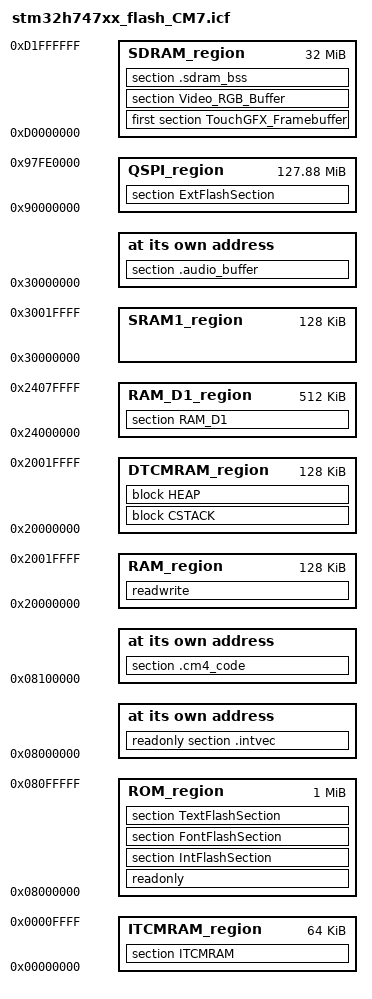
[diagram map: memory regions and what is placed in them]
/*###ICF### Section handled by ICF editor, don't touch! ****/
/*-Editor annotation file-*/
/* IcfEditorFile="$TOOLKIT_DIR$\config\ide\IcfEditor\cortex_v1_0.xml" */
/*-Specials-*/
/*-Start of  symbols-Auto-generated By STM32CubeMX*/
define symbol __ICFEDIT_region_ITCMRAM_start__ =0x00000000;
define symbol __ICFEDIT_region_ITCMRAM_end__ =0xFFFF;
define symbol __ICFEDIT_region_RAM_D1_start__ =0x24000000;
define symbol __ICFEDIT_region_RAM_D1_end__ =0x2407FFFF;
/*-End of MX Symbols*/

define symbol __ICFEDIT_intvec_start__ = 0x08000000;
/*-Memory Regions-*/
define symbol __ICFEDIT_region_ROM_start__     = 0x08000000;
define symbol __ICFEDIT_region_ROM_end__       = 0x80FFFFF;
define symbol __ICFEDIT_region_RAM_start__     = 0x20000000;
define symbol __ICFEDIT_region_RAM_end__       = 0x2001FFFF;
define symbol __ICFEDIT_region_ITCMRAM_start__ = 0x00000000;
define symbol __ICFEDIT_region_ITCMRAM_end__   = 0x0000FFFF;
define symbol __ICFEDIT_region_DTCMRAM_start__ = 0x20000000;
define symbol __ICFEDIT_region_DTCMRAM_end__   = 0x2001FFFF;
define symbol __ICFEDIT_region_SRAM1_start__   = 0x30000000;
define symbol __ICFEDIT_region_SRAM1_end__     = 0x3001FFFF;
/*-Sizes-*/
define symbol __ICFEDIT_size_cstack__ = 0x2000;  /* 8KB — IAR reported 96% used at 4KB */
define symbol __ICFEDIT_size_heap__   = 0x1000;
/**** End of ICF editor section. ###ICF###*/

/*-Quad-SPI Memory Regions-*/
define symbol __ICFEDIT_region_SDRAM_start__   = 0xD0000000;
define symbol __ICFEDIT_region_SDRAM_end__     = 0xD1FFFFFF;
define symbol __ICFEDIT_region_QSPI_start__    = 0x90000000;
define symbol __ICFEDIT_region_QSPI_end__      = 0x97FE0000;

define memory mem with size = 4G;
/*-Start of  Regions- Auto-generated By STM32CubeMX*/
define region ITCMRAM_region      = mem:[from __ICFEDIT_region_ITCMRAM_start__      to __ICFEDIT_region_ITCMRAM_end__];
define region RAM_D1_region      = mem:[from __ICFEDIT_region_RAM_D1_start__      to __ICFEDIT_region_RAM_D1_end__];
/*-End of MX Regions-*/

define region ROM_region      = mem:[from __ICFEDIT_region_ROM_start__   to __ICFEDIT_region_ROM_end__];
define region RAM_region      = mem:[from __ICFEDIT_region_RAM_start__   to __ICFEDIT_region_RAM_end__];
define region ITCMRAM_region  = mem:[from __ICFEDIT_region_ITCMRAM_start__ to __ICFEDIT_region_ITCMRAM_end__];
define region DTCMRAM_region  = mem:[from __ICFEDIT_region_DTCMRAM_start__ to __ICFEDIT_region_DTCMRAM_end__];
define region SRAM1_region    = mem:[from __ICFEDIT_region_SRAM1_start__ to __ICFEDIT_region_SRAM1_end__];

define region SDRAM_region    = mem:[from __ICFEDIT_region_SDRAM_start__      to __ICFEDIT_region_SDRAM_end__];
define region QSPI_region     = mem:[from __ICFEDIT_region_QSPI_start__    to __ICFEDIT_region_QSPI_end__];

define block CSTACK    with alignment = 8, size = __ICFEDIT_size_cstack__   { };
define block HEAP      with alignment = 8, size = __ICFEDIT_size_heap__     { };


initialize by copy { readwrite };
do not initialize  { section .noinit, section Video_RGB_Buffer, section TouchGFX_Framebuffer,
/*-Start of  Sections- Auto-generated By STM32CubeMX*/
place in ITCMRAM_region  { section ITCMRAM};
place in RAM_D1_region  { section RAM_D1};
/*-end of MX Sections-*/

                     section .sdram_bss,
                     section .audio_buffer };

place at address mem:__ICFEDIT_intvec_start__ { readonly section .intvec };
place at address mem:0x08100000 { section .cm4_code };

place in ROM_region   { readonly, section IntFlashSection, section FontFlashSection, section TextFlashSection };
place in RAM_region   { readwrite };

/* Stack/Heap in DTCM — fastest M7 access, no DMA contention */
place in DTCMRAM_region { block CSTACK, block HEAP };

/* Audio DMA buffers in D2 SRAM1 — non-cacheable, DMA1 accessible */
place at address mem:0x30000000 { section .audio_buffer };

place in QSPI_region   { section ExtFlashSection };
place in SDRAM_region  { first section TouchGFX_Framebuffer, section Video_RGB_Buffer,
                         section .sdram_bss };
